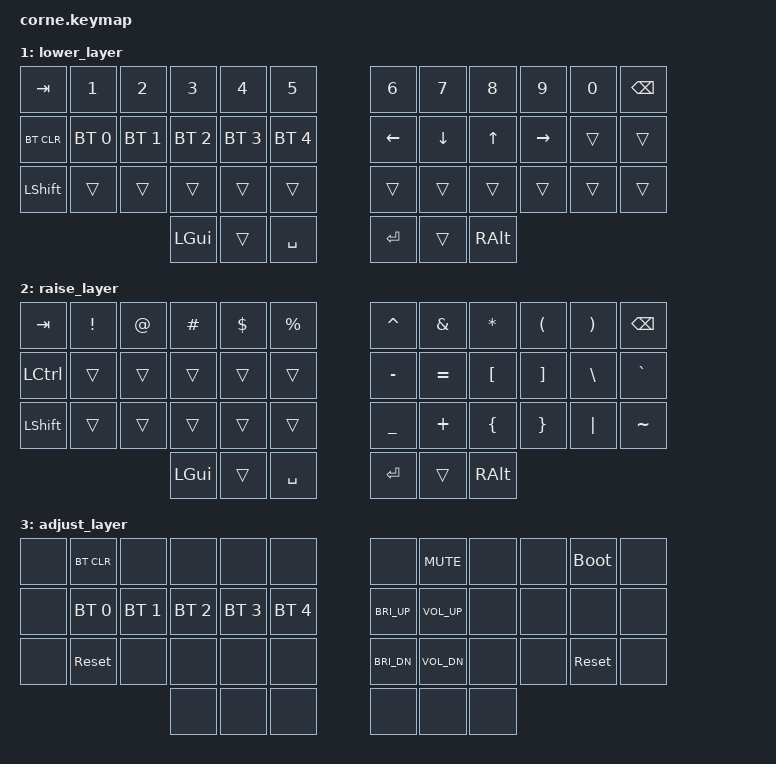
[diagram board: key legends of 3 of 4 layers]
/*
 * Copyright (c) 2020 The ZMK Contributors
 *
 * SPDX-License-Identifier: MIT
 */

/*
 * This is a keymap for Samoklava, a Corne-compatible wireless keyboard. You can use this keymap with a Corne as well.
 * To compile, run these commands:
 *
 *   west build -d build/left -b nice_nano_v2 -- -DSHIELD=corne_left -DZMK_CONFIG='../../samoklava-zmk-config/config'
 *   west build -d build/right -b nice_nano_v2 -- -DSHIELD=corne_right -DZMK_CONFIG='../../samoklava-zmk-config/config'
 *   cp build/left/zephyr/zmk.uf2 ~/Desktop/left.uf2
 *   cp build/right/zephyr/zmk.uf2 ~/Desktop/right.uf2
 */

#include <behaviors.dtsi>
#include <dt-bindings/zmk/keys.h>
#include <dt-bindings/zmk/bt.h>


#define DEFAULT 0
#define LOWER   1
#define RAISE   2
#define ADJUST  3
#define LWR LOWER
#define RSE RAISE
#define ADJ ADJUST

&mt {
    quick-tap-ms = <180>;
    tapping-term-ms = <250>;
};

&lt {
    quick_tap_ms = <200>;
    tapping-term-ms = <180>;
};

/ {
        behaviors {
            //                 Key positions
            //       0  1  2  3  4  5    6  7  8  9 10 11
            //      12 13 14 15 16 17   18 19 20 21 22 23
            //      24 25 26 27 28 29   30 31 32 33 34 35
            //               36 37 38   39 40 41

            hml: homerow_mods_left {
                compatible = "zmk,behavior-hold-tap";
                label = "HOMEROW_MODS_LEFT";
                #binding-cells = <2>;
                flavor = "tap-preferred";
                tapping-term-ms = <200>;
                quick-tap-ms = <200>;
                require-prior-idle-ms = <120>;
                bindings = <&kp>, <&kp>;
                hold-trigger-key-positions = <
                                         6  7  8  9 10
                       13 14 15 16      18 19 20 21 22
                          26            30 31 32 33 34
                             36 37 38   39 40 41
                    >;    // <---[[right-hand keys + all homerow mods + all thumbs]]
            };

            hsl: homerow_shift_left {
                compatible = "zmk,behavior-hold-tap";
                label = "HOMEROW_SHIFT_LEFT";
                #binding-cells = <2>;
                flavor = "tap-preferred";
                tapping-term-ms = <200>;
                quick-tap-ms = <200>;
                require-prior-idle-ms = <50>;
                bindings = <&kp>, <&kp>;
                hold-trigger-key-positions = <
                                         6  7  8  9 10
                       13 14 15 16      18 19 20 21 22
                          26            30 31 32 33 34
                             36 37 38   39 40 41
                    >;    // <---[[right-hand keys + all homerow mods + all thumbs]]
            };

            hmr: homerow_mods_right {
                compatible = "zmk,behavior-hold-tap";
                label = "HOMEROW_MODS_RIGHT";
                #binding-cells = <2>;
                flavor = "tap-preferred";
                tapping-term-ms = <200>;
                quick-tap-ms = <200>;
                require-prior-idle-ms = <120>;
                bindings = <&kp>, <&kp>;
                hold-trigger-key-positions = <
                        1  2  3  4  5
                       13 14 15 16 17      19 20 21 22
                       25 26 27 28 29            33
                             36 37 38   39 40 41
                    >;    // <---[[left-hand keys + all homerow mods + all thumbs]]
            };

            hsr: homerow_shift_right {
                compatible = "zmk,behavior-hold-tap";
                label = "HOMEROW_SHIFT_RIGHT";
                #binding-cells = <2>;
                flavor = "tap-preferred";
                tapping-term-ms = <200>;
                quick-tap-ms = <200>;
                require-prior-idle-ms = <50>;
                bindings = <&kp>, <&kp>;
                hold-trigger-key-positions = <
                        1  2  3  4  5
                       13 14 15 16 17      19 20 21 22
                       25 26 27 28 29            33
                             36 37 38   39 40 41
                    >;    // <---[[left-hand keys + all homerow mods + all thumbs]]
            };
        };

        combos {
           compatible = "zmk,combos";
           combo_lpar {
              timeout-ms = <50>;
              key-positions = <25 26>;
              bindings = <&kp LPAR>;
           };

           combo_rpar {
              timeout-ms = <50>;
              key-positions = <33 34>;
              bindings = <&kp RPAR>;
           };
        };

        conditional_layers {
            compatible = "zmk,conditional-layers";
            tri_layer {
                if-layers = <LOWER RAISE>;
                then-layer = <ADJUST>;
            };
        };

        keymap {
                compatible = "zmk,keymap";

                default_layer {
                        bindings = <
   &none &kp Q        &kp W         &kp E        &kp R         &kp T             &kp Y         &kp U            &kp I           &kp O            &kp P          &none
   &none &hml LCMD A  &hml RALT S   &hml LCTRL D &hsl LSHFT F  &kp G             &kp H         &hsr RSHFT J     &hmr RCTRL K    &hmr RALT L      &hmr RCMD SEMI &none
   &none &kp Z        &hml LALT X   &kp C        &kp V         &kp B             &kp N         &kp M            &kp COMMA       &hmr LALT DOT    &kp FSLH       &none
                                    &lt RSE ESC  &lt LWR QUOT  &kp SPACE         &mt RSHFT RET &lt RSE BSPC     &lt LWR TAB
                        >;
                };
                lower_layer {
                        bindings = <
   &none &kp N1       &kp N2       &kp N3        &kp N4        &kp N5            &kp N6        &kp N7           &kp N8           &kp N9          &kp N0         &none
   &none &kp LCMD     &kp RALT     &kp LCTRL     &kp LSHFT     &none             &kp LEFT      &hsr RSHFT DOWN  &hmr RCTRL UP    &hmr RALT RIGHT &kp RCMD       &none
   &none &none        &kp LALT     &none         &kp Y         &none             &kp HOME      &kp PG_DN        &kp PG_UP        &hmr LALT END   &caps_word     &none
                                   &lt RSE ESC   &lt LWR QUOT  &kp SPACE         &mt RSHFT RET &mo RSE          &lt LWR TAB
                        >;
                };
                raise_layer {
                        bindings = <
   &none &kp EXCL     &kp AT       &kp HASH      &kp DLLR      &kp PRCNT         &kp CARET     &kp AMPS         &kp KP_MULTIPLY  &kp LPAR        &kp RPAR       &none
   &none &hml LCMD F1 &hml RALT F2 &hml LCTRL F3 &hsl LSHFT F4 &kp F5            &kp MINUS     &hsr RSHFT EQUAL &hmr RCTRL LBKT  &hmr RALT RBKT  &hmr RCMD BSLH &none
   &none &kp F6       &hml LALT F7 &kp F8        &kp F9        &kp F10           &kp UNDER     &kp PLUS         &kp LBRC         &kp RBRC        &kp PIPE       &none
                                   &lt RSE ESC   &mo LWR       &kp GRAVE         &mt RSHFT RET &lt RSE BSPC     &lt LWR TAB
                        >;
                };
                adjust_layer {
                        bindings = <
   &none &bt BT_CLR   &none        &none         &none         &none             &none         &kp K_MUTE       &none            &none           &bootloader   &none
   &none &bt BT_SEL 0 &bt BT_SEL 1 &bt BT_SEL 2  &bt BT_SEL 3  &bt BT_SEL 4      &kp C_BRI_UP  &kp C_VOL_UP     &none            &none           &none         &none
   &none &sys_reset   &none        &none         &none         &none             &kp C_BRI_DN  &kp C_VOL_DN     &none            &none           &sys_reset    &none
                                   &none         &none         &none             &none         &none            &none
                        >;
                };
        };
};

/*
 * Copyright (c) 2020 The ZMK Contributors
 *
 * SPDX-License-Identifier: MIT
 */

#include <behaviors.dtsi>
#include <dt-bindings/zmk/keys.h>
#include <dt-bindings/zmk/bt.h>

/ {
        keymap {
                compatible = "zmk,keymap";

                default_layer {
// -----------------------------------------------------------------------------------------
// |  Escape |  F1 |  F2 |  F3 |  F4 |  F5 |   |  F6 |  F7  |  F8 |  F9 | F10 |  +   |
// |  `   |  1  |  2  |  3  |  4  |  5  |   |  6  |  7   |  8  |  9  |  0  |  -   |
// |  TAB |  Q  |  W  |  E  |  R  |  T  |   |  Y  |  U   |  I  |  O  |  P  | BKSP |
// | CTRL |  A  |  S  |  D  |  F  |  G  |   |  H  |  J   |  K  |  L  |  ;  |  '   |
// | SHFT |  Z  |  X  |  C  |  V  |  B  |   |  N  |  M   |  ,  |  .  |  /  | ESC  |
//                    | GUI | LWR | SPC |   | ENT | RSE  | ALT |
                        bindings = <
   &kp ESCAPE   &kp F1 &kp F2 &kp F3 &kp F4 &kp F5   &kp F6 &kp F7  &kp F8     &kp F9   &kp F10    &kp PLUS
   &kp GRAVE   &kp 1 &kp 2 &kp 3 &kp 4 &kp 5   &kp 6 &kp 7  &kp 8     &kp 9   &kp 10    &kp MINUS
   &kp TAB   &kp Q &kp W &kp E &kp R &kp T   &kp Y &kp U  &kp I     &kp O   &kp P    &kp BSPC
   &kp LCTRL &kp A &kp S &kp D &kp F &kp G   &kp H &kp J  &kp K     &kp L   &kp SEMI &kp SQT
   &kp LSHFT &kp Z &kp X &kp C &kp V &kp B   &kp N &kp M  &kp COMMA &kp DOT &kp FSLH &kp ESC
                  &kp LGUI &mo 1 &kp SPACE   &kp RET &mo 2 &kp RALT
                        >;
                };
                lower_layer {
// -----------------------------------------------------------------------------------------
// |  TAB |  1  |  2  |  3  |  4  |  5  |   |  6  |  7  |  8  |  9  |  0  | BKSP |
// | BTCLR| BT1 | BT2 | BT3 | BT4 | BT5 |   | LFT | DWN |  UP | RGT |     |      |
// | SHFT |     |     |     |     |     |   |     |     |     |     |     |      |
//                    | GUI |     | SPC |   | ENT |     | ALT |
                        bindings = <
   &kp TAB    &kp N1       &kp N2       &kp N3       &kp N4       &kp N5         &kp N6   &kp N7   &kp N8 &kp N9    &kp N0 &kp BSPC
   &bt BT_CLR &bt BT_SEL 0 &bt BT_SEL 1 &bt BT_SEL 2 &bt BT_SEL 3 &bt BT_SEL 4   &kp LEFT &kp DOWN &kp UP &kp RIGHT &trans &trans
   &kp LSHFT  &trans       &trans       &trans       &trans       &trans         &trans   &trans   &trans &trans    &trans &trans
                                    &kp LGUI     &trans       &kp SPACE      &kp RET  &trans   &kp RALT
                        >;
                };

                raise_layer {
// -----------------------------------------------------------------------------------------
// |  TAB |  !  |  @  |  #  |  $  |  %  |   |  ^  |  &  |  *  |  (  |  )  | BKSP |
// | CTRL |     |     |     |     |     |   |  -  |  =  |  [  |  ]  |  \  |  `   |
// | SHFT |     |     |     |     |     |   |  _  |  +  |  {  |  }  | "|" |  ~   |
//                    | GUI |     | SPC |   | ENT |     | ALT |
                        bindings = <
   &kp  TAB  &kp EXCL &kp AT &kp HASH &kp DLLR &kp PRCNT   &kp CARET &kp AMPS  &kp ASTRK &kp LPAR &kp RPAR &kp BSPC
   &kp LCTRL &trans   &trans &trans   &trans   &trans      &kp MINUS &kp EQUAL &kp LBKT  &kp RBKT &kp BSLH &kp GRAVE
   &kp LSHFT &trans   &trans &trans   &trans   &trans      &kp UNDER &kp PLUS  &kp LBRC  &kp RBRC &kp PIPE &kp TILDE
                             &kp LGUI &trans   &kp SPACE   &kp RET   &trans    &kp RALT
                        >;
                };
        };
};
